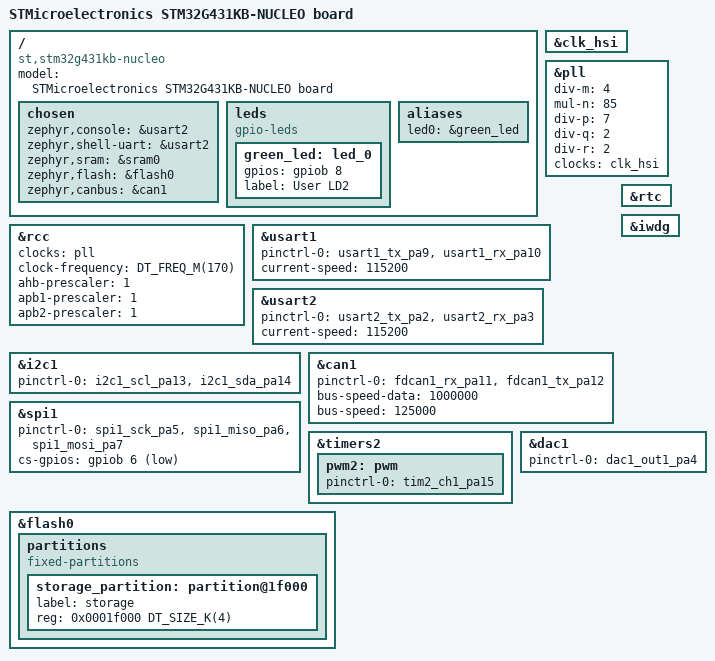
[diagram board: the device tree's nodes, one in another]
/*
 *
 * SPDX-License-Identifier: Apache-2.0
 */

/dts-v1/;
#include <st/g4/stm32g431Xb.dtsi>
#include <st/g4/stm32g431k(6-8-b)tx-pinctrl.dtsi>
#include "arduino_nano_r3_connector.dtsi"

/ {
	model = "STMicroelectronics STM32G431KB-NUCLEO board";
	compatible = "st,stm32g431kb-nucleo";

	chosen {
		zephyr,console = &usart2;
		zephyr,shell-uart = &usart2;
		zephyr,sram = &sram0;
		zephyr,flash = &flash0;
		zephyr,canbus = &can1;
	};

	leds {
		compatible = "gpio-leds";
		green_led: led_0 {
			gpios = <&gpiob 8 GPIO_ACTIVE_HIGH>;
			label = "User LD2";
		};
	};
	aliases {
		led0 = &green_led;
	};

};

&clk_hsi {
	status = "okay";
};

&pll {
	div-m = <4>;
	mul-n = <85>;
      div-p = <7>;
	div-q = <2>;
	div-r = <2>;
	clocks = <&clk_hsi>;
	status = "okay";
};

&rcc {
	clocks = <&pll>;
	clock-frequency = <DT_FREQ_M(170)>;
	ahb-prescaler = <1>;
	apb1-prescaler = <1>;
	apb2-prescaler = <1>;
};

&usart1 {
	pinctrl-0 = <&usart1_tx_pa9 &usart1_rx_pa10>;
	pinctrl-names = "default";
	current-speed = <115200>;
	status = "okay";
};

&usart2 {
	pinctrl-0 = <&usart2_tx_pa2 &usart2_rx_pa3>;
	pinctrl-names = "default";
	current-speed = <115200>;
	status = "okay";
};

&i2c1 {
	pinctrl-0 = <&i2c1_scl_pa13 &i2c1_sda_pa14>;
	pinctrl-names = "default";
	status = "okay";
};

&can1 {
	pinctrl-0 = <&fdcan1_rx_pa11 &fdcan1_tx_pa12>;
	pinctrl-names = "default";
	status = "okay";
	bus-speed-data = <1000000>;
	bus-speed = <125000>;
};

&spi1 {
	pinctrl-0 = <&spi1_sck_pa5 &spi1_miso_pa6 &spi1_mosi_pa7>;
	pinctrl-names = "default";
	cs-gpios = <&gpiob 6 (GPIO_ACTIVE_LOW | GPIO_PULL_UP)>;
	status = "okay";
};


&timers2 {
	status = "okay";

	pwm2: pwm {
		status = "okay";
		pinctrl-0 = <&tim2_ch1_pa15>;
		pinctrl-names = "default";
	};
};

&rtc {
	status = "okay";
};

&flash0 {

	partitions {
		compatible = "fixed-partitions";
		#address-cells = <1>;
		#size-cells = <1>;

		/* Set 4Kb of storage at the end of the 128Kb of flash */
		storage_partition: partition@1f000 {
			label = "storage";
			reg = <0x0001f000 DT_SIZE_K(4)>;
		};
	};
};

&iwdg {
	status = "okay";
};

&dac1 {
	status = "okay";
	pinctrl-0 = <&dac1_out1_pa4>;
	pinctrl-names = "default";
};
